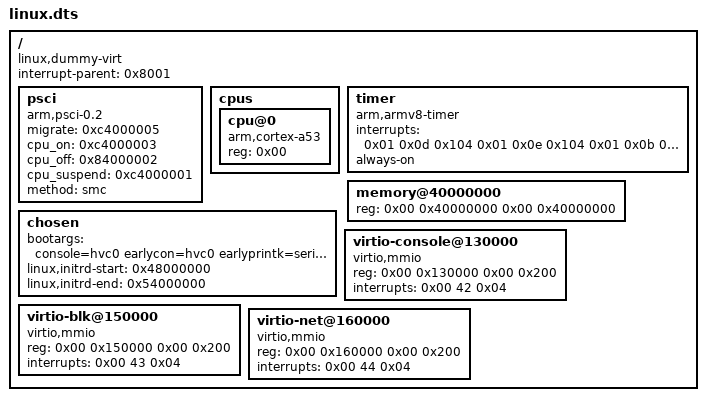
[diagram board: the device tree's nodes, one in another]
/*
 * Copyright 2025, UNSW
 *
 * SPDX-License-Identifier: BSD-2-Clause
 */

/dts-v1/;

/ {
	interrupt-parent = <0x8001>;
	#size-cells = <0x02>;
	#address-cells = <0x02>;
	compatible = "linux,dummy-virt";

	psci {
		migrate = <0xc4000005>;
		cpu_on = <0xc4000003>;
		cpu_off = <0x84000002>;
		cpu_suspend = <0xc4000001>;
		method = "smc";
		compatible = "arm,psci-0.2\0arm,psci";
	};

	cpus {
		#size-cells = <0x00>;
		#address-cells = <0x01>;

		cpu@0 {
			reg = <0x00>;
			compatible = "arm,cortex-a53";
			device_type = "cpu";
		};
	};

	timer {
		interrupts = <0x01 0x0d 0x104 0x01 0x0e 0x104 0x01 0x0b 0x104 0x01 0x0a 0x104>;
		always-on;
		compatible = "arm,armv8-timer\0arm,armv7-timer";
	};

    memory@40000000 {
		reg = <0x00 0x40000000 0x00 0x40000000>;
		device_type = "memory";
	};

	chosen {
		/* @@FOUNDRY_EXTRA_BOOTARGS@@ is a substitution token, not a real
		 * value — see virtio.mk's client_vm/vm.dts rule. QEMU's `-append`
		 * only works with the `-kernel` boot path, not the `-device
		 * loader` mechanism this seL4/Microkit image uses, so runtime
		 * config (e.g. `foundry.mode=smoketest` for os-mediakit's G4
		 * smoke-test path) has to be baked into the DTB at build time
		 * instead. Ported from project-totebox's own identical fix to
		 * this same shared vendor-libvmm example (their Session 24,
		 * found live trying to inject boot-time config the same way) —
		 * adopting their proven mechanism rather than re-deriving it.
		 * `FOUNDRY_EXTRA_BOOTARGS='foundry.mode=smoketest' make ...`
		 */
		bootargs = "console=hvc0 earlycon=hvc0 earlyprintk=serial debug loglevel=8 @@FOUNDRY_EXTRA_BOOTARGS@@";
		linux,initrd-start = <0x48000000>;
		linux,initrd-end = <0x54000000>;
	};

	virtio-console@130000 {
		compatible = "virtio,mmio";
		reg = <0x00 0x130000 0x00 0x200>;
		interrupts = <0x00 42 0x04>;
	};

	virtio-blk@150000 {
		compatible = "virtio,mmio";
		reg = <0x00 0x150000 0x00 0x200>;
		interrupts = <0x00 43 0x04>;
	};

	virtio-net@160000 {
		compatible = "virtio,mmio";
		reg = <0x00 0x160000 0x00 0x200>;
		interrupts = <0x00 44 0x04>;
	};
};
